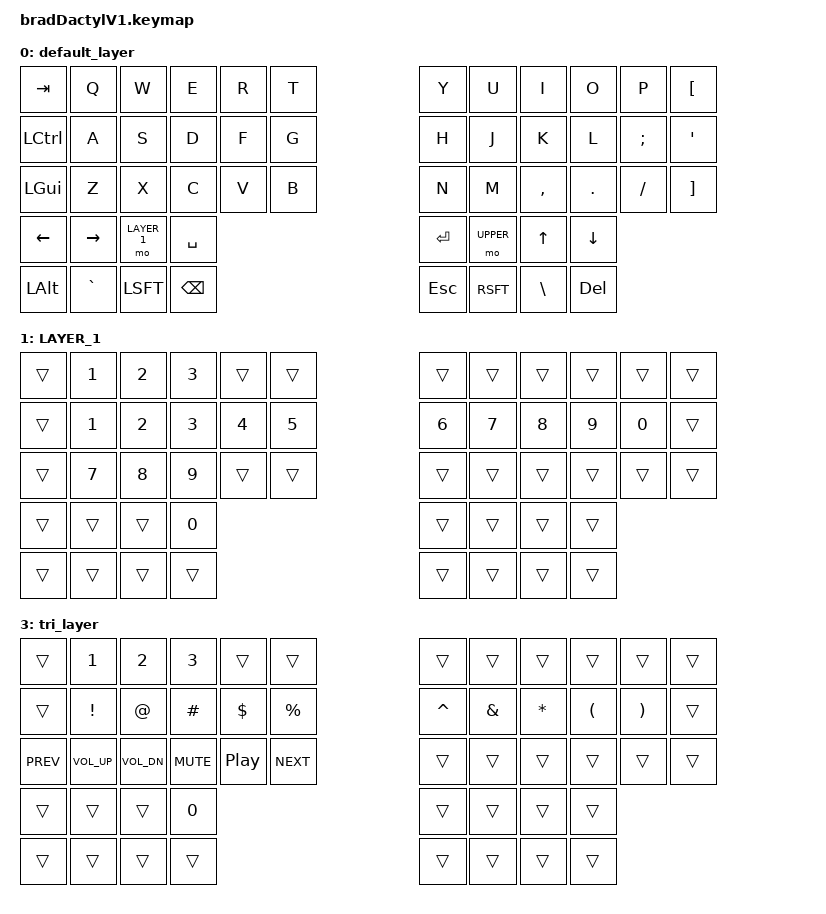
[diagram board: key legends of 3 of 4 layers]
#include <behaviors.dtsi>
#include <dt-bindings/zmk/keys.h>
#include <dt-bindings/zmk/bt.h>

#define LAYER_0 0
#define LAYER_1 1
#define UPPER 2
#define tri_layer 3


/ {
    conditional_layers {
        compatible = "zmk,conditional-layers";

        tri_layer {
            if-layers = <1 2>;
            then-layer = <3>;
        };
    };
    keymap {
        compatible = "zmk,keymap";

        default_layer {
            // ----------------------------------------------------------------------------------------------------------------------------------
            // TAB |    Q    |    W    |    E    |    R    |    T    |                   |    Y    |    U    |    I    |    O    |    P    |   [
            // Ctrl|    A    |    S    |    D    |    F    |    G    |                   |    H    |    J    |    K    |    L    |    ;    |   '
            //SUPER|    Z    |    X    |    C    |    V    |    B    |                   |    N    |    M    |    ,    |    .    |    /    |   ]
            //     |       | Lft Arrow | Rht Arrow |     |         |                     |         |        | Up Arrow | Dwn Arrow |       |
            //                              |  Layer up    |   Space   |            |   ENTER   | Layer dwn  |
            //                              |    Shift     |    BSPC   |            |    Escape |   Shift   |
            //                              |    L-Alt    |      `     |            |     \     |   Delete  |
            bindings = <
                &kp TAB    &kp Q    &kp W    &kp E    &kp R    &kp T                           &kp Y     &kp U     &kp I     &kp O     &kp P    &kp LBKT
                &kp LCTRL  &kp A    &kp S    &kp D    &kp F    &kp G                           &kp H     &kp J     &kp K     &kp L     &kp SEMI &kp QUOT
                &kp LGUI   &kp Z    &kp X    &kp C    &kp V    &kp B                           &kp N     &kp M     &kp COMMA &kp DOT   &kp FSLH &kp RBKT
                &kp LEFT &kp RIGHT &mo LAYER_1 &kp SPACE                                       &kp RET   &mo UPPER &kp UP    &kp DOWN
                &kp LALT &kp GRAVE &kp LSFT    &kp BSPC                                        &kp ESC   &kp RSFT    &kp BSLH  &kp DEL
                >;
        };
        LAYER_1 {
            bindings = <
                &trans  &kp N1    &kp N2    &kp N3    &trans  &trans                           &trans  &trans  &trans  &trans  &trans  &trans
                &trans  &kp N1    &kp N2    &kp N3    &kp N4  &kp N5                           &kp N6  &kp N7  &kp N8  &kp N9  &kp N0  &trans
                &trans  &kp N7    &kp N8    &kp N9    &trans  &trans                           &trans  &trans  &trans  &trans  &trans  &trans
                &trans  &trans    &trans    &kp N0                                             &trans  &trans  &trans  &trans
                &trans  &trans    &trans    &trans                                             &trans  &trans  &trans  &trans
                >;
        };
        UPPER {
            bindings = <
                &trans  &kp N1    &kp N2    &kp N3    &trans     &trans                        &trans     &trans    &trans    &trans    &trans    &trans
                &trans  &kp EXCL  &kp AT    &kp POUND &kp DOLLAR &kp PRCNT                     &kp CARET  &kp AMPS  &kp STAR  &kp LPAR  &kp RPAR  &trans
                &trans  &kp N7    &kp N8    &kp N9    &trans     &trans                        &kp UNDER  &kp MINUS &kp PLUS  &kp EQUAL &trans    &trans
                &trans  &trans    &trans    &kp N0                                             &trans     &trans    &trans    &trans    &trans
                &trans  &trans    &trans    &trans                                             &trans     &trans    &trans    &trans
                >;
        };
        tri_layer {
            bindings = <
                &trans  &kp N1    &kp N2    &kp N3    &trans     &trans                        &trans     &trans    &trans    &trans    &trans    &trans
                &trans  &kp EXCL  &kp AT    &kp POUND &kp DOLLAR &kp PRCNT                     &kp CARET  &kp AMPS  &kp STAR  &kp LPAR  &kp RPAR  &trans
                &kp C_PREV  &kp C_VOL_UP &kp C_VOL_DN &kp C_MUTE &kp C_PLAY_PAUSE &kp C_NEXT      &trans     &trans    &trans    &trans    &trans    &trans
                &trans  &trans    &trans    &kp N0                                             &trans     &trans    &trans    &trans
                &trans  &trans    &trans    &trans                                             &trans     &trans    &trans    &trans
                >;
        };
    };
};
